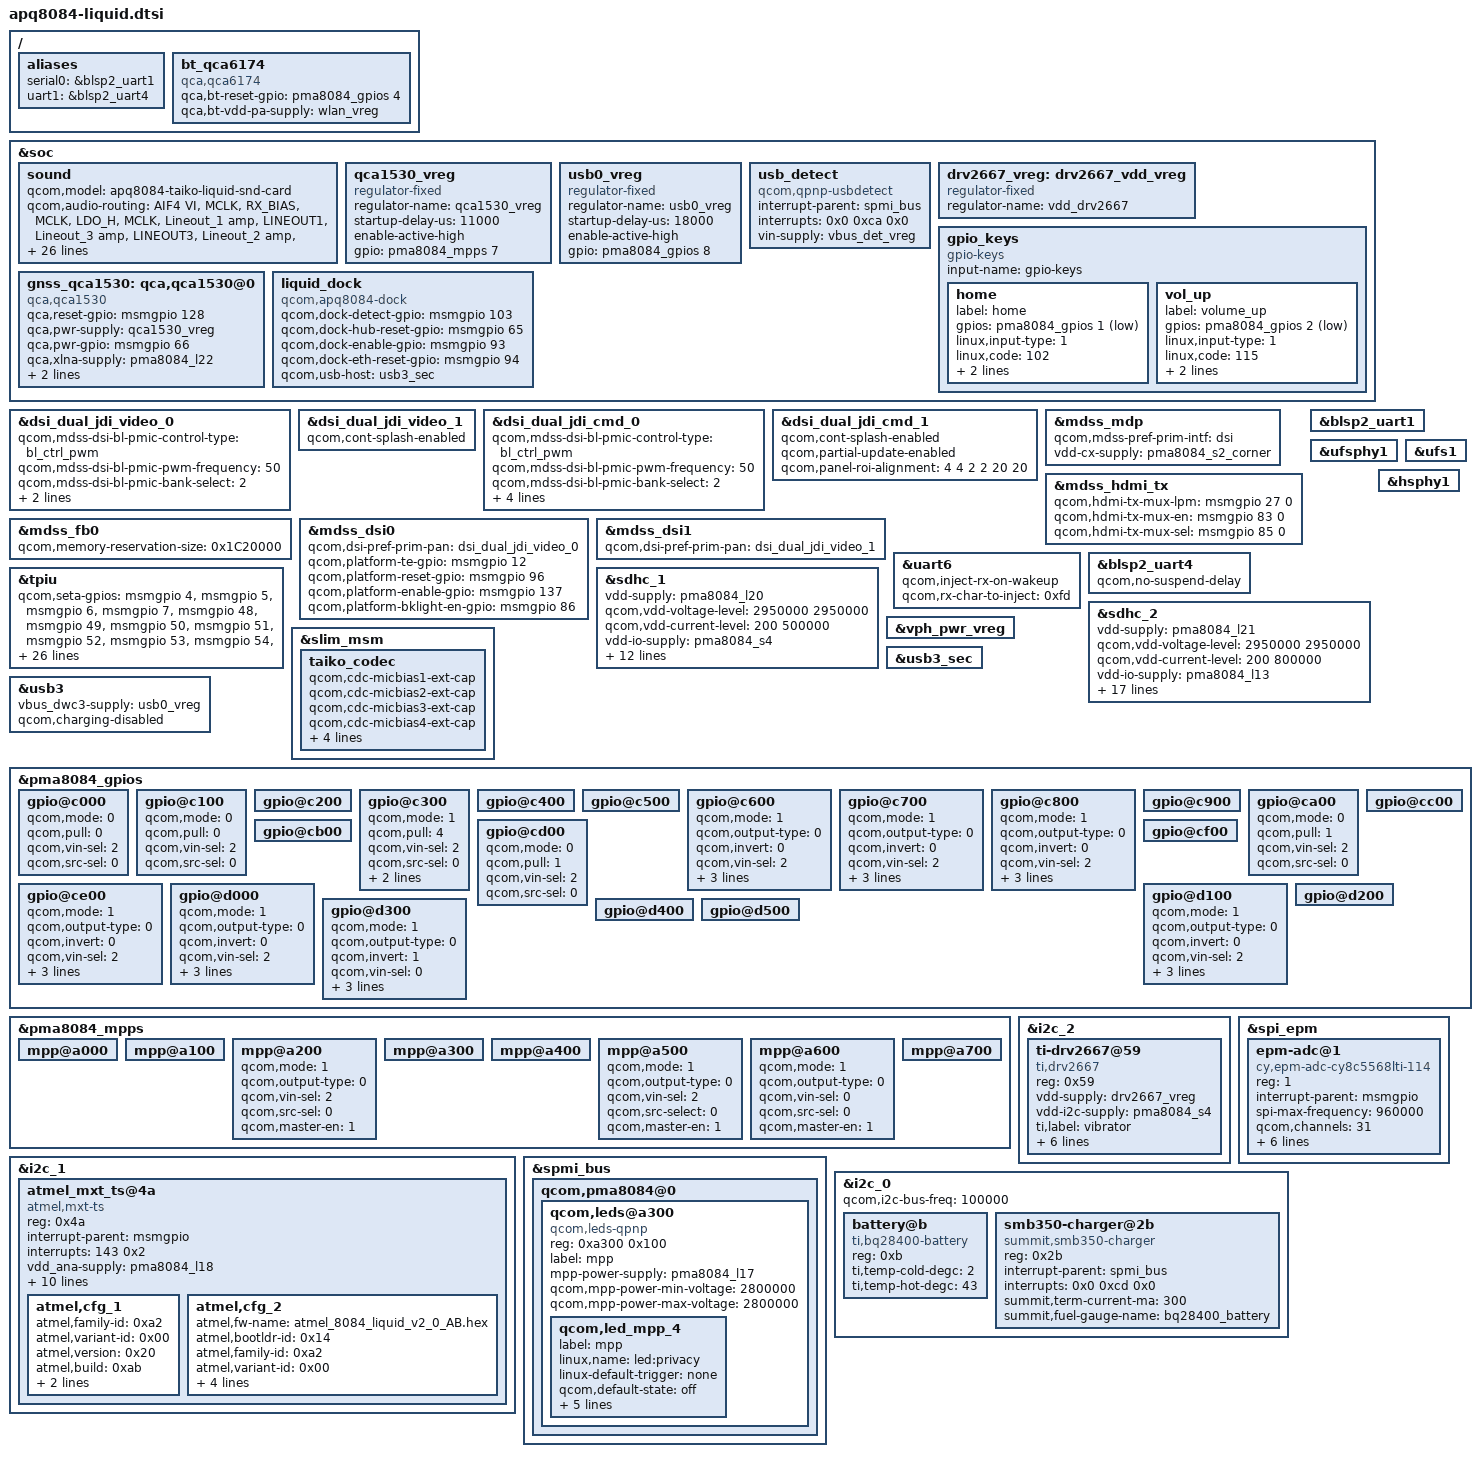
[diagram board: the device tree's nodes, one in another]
/* Copyright (c) 2013-2014, The Linux Foundation. All rights reserved.
 *
 * This program is free software; you can redistribute it and/or modify
 * it under the terms of the GNU General Public License version 2 and
 * only version 2 as published by the Free Software Foundation.
 *
 * This program is distributed in the hope that it will be useful,
 * but WITHOUT ANY WARRANTY; without even the implied warranty of
 * MERCHANTABILITY or FITNESS FOR A PARTICULAR PURPOSE.  See the
 * GNU General Public License for more details.
 */

/ {
	aliases {
		serial0 = &blsp2_uart1;
		uart1 = &blsp2_uart4;
	};

	bt_qca6174 {
		compatible = "qca,qca6174";
		qca,bt-reset-gpio = <&pma8084_gpios 4 0>; /* BT_EN */
		qca,bt-vdd-pa-supply = <&wlan_vreg>;
	};
};

&soc {
	sound {
		qcom,model = "apq8084-taiko-liquid-snd-card";

		qcom,audio-routing =
			"AIF4 VI", "MCLK",
			"RX_BIAS", "MCLK",
			"LDO_H", "MCLK",
			"Lineout_1 amp", "LINEOUT1",
			"Lineout_3 amp", "LINEOUT3",
			"Lineout_2 amp", "LINEOUT2",
			"Lineout_4 amp", "LINEOUT4",
			"SPK_ultrasound amp", "SPK_OUT",
			"AMIC1", "MIC BIAS3 External",
			"MIC BIAS3 External", "Analog Mic7",
			"AMIC2", "MIC BIAS2 External",
			"MIC BIAS2 External", "Headset Mic",
			"AMIC3", "MIC BIAS2 External",
			"MIC BIAS2 External", "ANCLeft Headset Mic",
			"AMIC4", "MIC BIAS2 External",
			"MIC BIAS2 External", "ANCRight Headset Mic",
			"DMIC1", "MIC BIAS4 External",
			"MIC BIAS4 External", "Digital Mic4",
			"DMIC2", "MIC BIAS3 External",
			"MIC BIAS3 External", "Digital Mic3",
			"DMIC3", "MIC BIAS1 External",
			"MIC BIAS1 External", "Digital Mic2",
			"DMIC4", "MIC BIAS1 External",
			"MIC BIAS1 External", "Digital Mic1",
			"DMIC5", "MIC BIAS3 External",
			"MIC BIAS3 External", "Digital Mic5",
			"DMIC6", "MIC BIAS3 External",
			"MIC BIAS3 External", "Digital Mic6";

		qcom,cdc-micbias2-headset-only;
		qcom,hdmi-audio-rx;
		asoc-codec = <&stub_codec>, <&hdmi_audio>;
		asoc-codec-names = "msm-stub-codec.1", "msm-hdmi-audio-codec-rx";
		qcom,ext-spk-amp-supply = <&hdmi_vreg>;
		qcom,ext-spk-amp-gpio = <&pma8084_mpps 6 0>;
		qcom,dock-plug-det-irq = <&msmgpio 142 0>;
	};

	qca1530_vreg: qca1530_vreg {
		compatible = "regulator-fixed";
		regulator-name = "qca1530_vreg";
		startup-delay-us = <11000>; /* the on time of SMB209AN */
		enable-active-high;
		gpio = <&pma8084_mpps 7 0>;
	};

	usb0_vreg: usb0_vreg {
		compatible = "regulator-fixed";
		regulator-name = "usb0_vreg";
		startup-delay-us = <18000>; /* the on time of TPD4S214 */
		enable-active-high;
		gpio = <&pma8084_gpios 8 0>;
	};

	usb_detect {
		compatible = "qcom,qpnp-usbdetect";
		interrupt-parent = <&spmi_bus>;
		interrupts = <0x0 0xca 0x0>;  /* PMA8084 GPIO 11 */
		interrupt-names = "vbus_det_irq";
		vin-supply = <&vbus_det_vreg>;
	};

	drv2667_vreg: drv2667_vdd_vreg {
		compatible = "regulator-fixed";
		regulator-name = "vdd_drv2667";
	};

	gpio_keys {
		compatible = "gpio-keys";
		input-name = "gpio-keys";

		home {
			label = "home";
			gpios = <&pma8084_gpios 1 0x1>;
			linux,input-type = <1>;
			linux,code = <102>;
			gpio-key,wakeup;
			debounce-interval = <15>;
		};

		vol_up {
			label = "volume_up";
			gpios = <&pma8084_gpios 2 0x1>;
			linux,input-type = <1>;
			linux,code = <115>;
			gpio-key,wakeup;
			debounce-interval = <15>;
		};
	};

	gnss_qca1530: qca,qca1530@0 {
		compatible = "qca,qca1530";
		qca,reset-gpio = <&msmgpio 128 0>;
		qca,pwr-supply = <&qca1530_vreg>;
		qca,pwr-gpio = <&msmgpio 66 0>;
		qca,xlna-supply = <&pma8084_l22>;
		qca,xlna-voltage-level = <3000000 3000000>;
		qca,xlna-current-level = <90000 100>;
	};

	liquid_dock {
		compatible = "qcom,apq8084-dock";
		qcom,dock-detect-gpio = <&msmgpio 103 0>;
		qcom,dock-hub-reset-gpio = <&msmgpio 65 0>;
		qcom,dock-enable-gpio = <&msmgpio 93 0>;
		qcom,dock-eth-reset-gpio = <&msmgpio 94 0>;
		qcom,usb-host = <&usb3_sec>;
	};
};

#include "apq8084-mdss-panels.dtsi"

&dsi_dual_jdi_video_0 {
	qcom,mdss-dsi-bl-pmic-control-type = "bl_ctrl_pwm";
	qcom,mdss-dsi-bl-pmic-pwm-frequency = <50>;
	qcom,mdss-dsi-bl-pmic-bank-select = <2>;
	qcom,mdss-dsi-pwm-gpio = <&pma8084_gpios 7 0>;
	qcom,cont-splash-enabled;
};

&dsi_dual_jdi_video_1 {
	qcom,cont-splash-enabled;
};


&dsi_dual_jdi_cmd_0 {
	qcom,mdss-dsi-bl-pmic-control-type = "bl_ctrl_pwm";
	qcom,mdss-dsi-bl-pmic-pwm-frequency = <50>;
	qcom,mdss-dsi-bl-pmic-bank-select = <2>;
	qcom,mdss-dsi-pwm-gpio = <&pma8084_gpios 7 0>;
	qcom,cont-splash-enabled;
	/delete-property/ qcom,cmd-sync-wait-broadcast;
	qcom,partial-update-enabled;
	qcom,panel-roi-alignment = <4 4 2 2 20 20>;
};

&dsi_dual_jdi_cmd_1 {
	qcom,cont-splash-enabled;
	/delete-property/ qcom,cmd-sync-wait-broadcast;
	/delete-property/ qcom,cmd-sync-wait-trigger;
	qcom,partial-update-enabled;
	qcom,panel-roi-alignment = <4 4 2 2 20 20>;
};


&mdss_mdp {
	qcom,mdss-pref-prim-intf = "dsi";
	vdd-cx-supply = <&pma8084_s2_corner>;
};

&mdss_hdmi_tx {
        qcom,hdmi-tx-mux-lpm = <&msmgpio 27 0>;
        qcom,hdmi-tx-mux-en = <&msmgpio 83 0>;
        qcom,hdmi-tx-mux-sel = <&msmgpio 85 0>;
};

&mdss_fb0 {
	qcom,memory-reservation-size = <0x1C20000>;
};

&mdss_dsi0 {
	qcom,dsi-pref-prim-pan = <&dsi_dual_jdi_video_0>;
	qcom,platform-te-gpio = <&msmgpio 12 0>;
	qcom,platform-reset-gpio = <&msmgpio 96 0>;
	qcom,platform-enable-gpio = <&msmgpio 137 0>;
	qcom,platform-bklight-en-gpio = <&msmgpio 86 0>;
};

&mdss_dsi1 {
	qcom,dsi-pref-prim-pan = <&dsi_dual_jdi_video_1>;
};

&uart6 {
	qcom,inject-rx-on-wakeup;
	qcom,rx-char-to-inject = <0xfd>;
	status = "ok";
};

&blsp2_uart1 {
	status = "ok";
};

&blsp2_uart4 {
	qcom,no-suspend-delay;
	status = "ok";
};

/* CoreSight */
&tpiu {
	qcom,seta-gpios = <&msmgpio 4 0>,
			  <&msmgpio 5 0>,
			  <&msmgpio 6 0>,
			  <&msmgpio 7 0>,
			  <&msmgpio 48 0>,
			  <&msmgpio 49 0>,
			  <&msmgpio 50 0>,
			  <&msmgpio 51 0>,
			  <&msmgpio 52 0>,
			  <&msmgpio 53 0>,
			  <&msmgpio 54 0>,
			  <&msmgpio 55 0>,
			  <&msmgpio 56 0>,
			  <&msmgpio 57 0>,
			  <&msmgpio 63 0>,
			  <&msmgpio 64 0>,
			  <&msmgpio 75 0>,
			  <&msmgpio 122 0>;
	qcom,seta-gpios-func = <4 4 4 4 5 4 4 5 5 4 4 4 4 4 4 5 2 1>;
	qcom,seta-gpios-drv =  <7 7 7 7 7 7 7 7 7 7 7 7 7 7 7 7 7 7>;
	qcom,seta-gpios-pull = <0 0 0 0 0 0 0 0 0 0 0 0 0 0 0 0 0 0>;
	qcom,seta-gpios-dir =  <2 2 2 2 2 2 2 2 2 2 2 2 2 2 2 2 2 2>;

	qcom,setb-gpios = <&msmgpio 10 0>,
			  <&msmgpio 11 0>,
			  <&msmgpio 29 0>,
			  <&msmgpio 30 0>,
			  <&msmgpio 39 0>,
			  <&msmgpio 40 0>,
			  <&msmgpio 43 0>,
			  <&msmgpio 44 0>,
			  <&msmgpio 45 0>,
			  <&msmgpio 46 0>,
			  <&msmgpio 67 0>,
			  <&msmgpio 68 0>,
			  <&msmgpio 69 0>,
			  <&msmgpio 70 0>,
			  <&msmgpio 71 0>,
			  <&msmgpio 72 0>,
			  <&msmgpio 102 0>,
			  <&msmgpio 121 0>;
	qcom,setb-gpios-func = <4 4 5 4 4 4 4 4 4 4 3 3 2 4 3 3 2 1>;
	qcom,setb-gpios-drv =  <7 7 7 7 7 7 7 7 7 7 7 7 7 7 7 7 7 7>;
	qcom,setb-gpios-pull = <0 0 0 0 0 0 0 0 0 0 0 0 0 0 0 0 0 0>;
	qcom,setb-gpios-dir =  <2 2 2 2 2 2 2 2 2 2 2 2 2 2 2 2 2 2>;
};

&ufsphy1 {
	status = "ok";
};

&ufs1 {
	status = "ok";
};

&sdhc_1 {
	vdd-supply = <&pma8084_l20>;
	qcom,vdd-voltage-level = <2950000 2950000>;
	qcom,vdd-current-level = <200 500000>;

	vdd-io-supply = <&pma8084_s4>;
	qcom,vdd-io-always-on;
	qcom,vdd-io-voltage-level = <1800000 1800000>;
	qcom,vdd-io-current-level = <200 154000>;

	pinctrl-names = "active", "sleep";
	pinctrl-0 = <&sdc1_clk_on &sdc1_cmd_on &sdc1_data_on &sdc1_rclk_on>;
	pinctrl-1 = <&sdc1_clk_off &sdc1_cmd_off &sdc1_data_off &sdc1_rclk_off>;

	qcom,clk-rates = <400000 20000000 25000000 50000000 100000000 192000000 384000000>;
	qcom,nonremovable;
	qcom,bus-speed-mode = "HS400_1p8v", "HS200_1p8v", "DDR_1p8v";
	status = "ok";
};

&sdhc_2 {
	vdd-supply = <&pma8084_l21>;
	qcom,vdd-voltage-level = <2950000 2950000>;
	qcom,vdd-current-level = <200 800000>;

	vdd-io-supply = <&pma8084_l13>;
	qcom,vdd-io-voltage-level = <1800000 2950000>;
	qcom,vdd-io-current-level = <200 22000>;

	pinctrl-names = "active", "sleep";
	pinctrl-0 = <&sdc2_clk_on &sdc2_cmd_on &sdc2_data_on &sdhc2_cd_on>;
	pinctrl-1 = <&sdc2_clk_off &sdc2_cmd_off &sdc2_data_off &sdhc2_cd_off>;

	qcom,clk-rates = <400000 20000000 25000000 50000000 100000000 200000000>;
	qcom,bus-speed-mode = "SDR12", "SDR25", "SDR50", "DDR50", "SDR104";

	#address-cells = <0>;
	interrupt-parent = <&sdhc_2>;
	interrupts = <0 1 2>;
	#interrupt-cells = <1>;
	interrupt-map-mask = <0xffffffff>;
	interrupt-map = <0 &intc 0 125 0
			1 &intc 0 221 0
			2 &msmgpio 122 0x3>;
	interrupt-names = "hc_irq", "pwr_irq", "status_irq";
	cd-gpios = <&msmgpio 122 0x1>;
	wp-gpios = <&msmgpio 75 0x1>;

	status = "ok";
};

&vph_pwr_vreg {
	status = "ok";
};

&slim_msm {
	taiko_codec {
		qcom,cdc-micbias1-ext-cap;
		qcom,cdc-micbias2-ext-cap;
		qcom,cdc-micbias3-ext-cap;
		qcom,cdc-micbias4-ext-cap;

		/*
		 * Liquid has external spkrdrv supply. Give a dummy supply
		 * to make codec driver happy.
		 */
		cdc-vdd-spkdrv-supply = <&vph_pwr_vreg>;
		qcom,cdc-vdd-spkdrv-voltage = <0 0>;
		qcom,cdc-vdd-spkdrv-current = <0>;

		qcom,cdc-on-demand-supplies = "cdc-vdd-spkdrv";
	};
};

&usb3 {
	vbus_dwc3-supply = <&usb0_vreg>;
	qcom,charging-disabled;
};

&usb3_sec {
	status = "ok";
};

&hsphy1 {
	status = "ok";
};

&pma8084_gpios {
	gpio@c000 { /* GPIO 1 */
		qcom,mode = <0>;
		qcom,pull = <0>;
		qcom,vin-sel = <2>;
		qcom,src-sel = <0>;
	};

	gpio@c100 { /* GPIO 2 */
		qcom,mode = <0>;
		qcom,pull = <0>;
		qcom,vin-sel = <2>;
		qcom,src-sel = <0>;
	};

	gpio@c200 { /* GPIO 3 */
	};

	gpio@c300 { /* GPIO 4 */
                qcom,mode = <1>;         /* Digital output*/
                qcom,pull = <4>;         /* Pulldown 10uA */
                qcom,vin-sel = <2>;      /* VIN2 */
                qcom,src-sel = <0>;      /* GPIO */
                qcom,invert = <0>;       /* Invert */
                qcom,master-en = <1>;    /* Enable GPIO */
	};

	gpio@c400 { /* GPIO 5 */
	};

	gpio@c500 { /* GPIO 6 */
	};

	gpio@c600 { /* GPIO 7 */
		/* Backlight PWM */
		qcom,mode = <1>;		/* Digital output */
		qcom,output-type = <0>;		/* CMOS logic */
		qcom,invert = <0>;		/* Do not invert the output */
		qcom,vin-sel = <2>;		/* PMA8084 S4 = 1.8 V */
		qcom,src-sel = <2>;		/* Special Function 1=LPG 3 */
		qcom,out-strength = <3>;	/* High drive strength */
		qcom,master-en = <1>;
	};

	gpio@c700 { /* GPIO 8 */
		qcom,mode = <1>;		/* Digital output */
		qcom,output-type = <0>;		/* CMOS logic */
		qcom,invert = <0>;		/* Output low initially */
		qcom,vin-sel = <2>;		/* VPH_PWR */
		qcom,src-sel = <0>;		/* Constant */
		qcom,out-strength = <1>;	/* Low */
		qcom,master-en = <1>;		/* Enable GPIO */
	};

	gpio@c800 { /* GPIO 9 */
		qcom,mode = <1>;		/* Digital output */
		qcom,output-type = <0>;		/* CMOS logic */
		qcom,invert = <0>;		/* Output low initially */
		qcom,vin-sel = <2>;		/* VPH_PWR */
		qcom,src-sel = <0>;		/* Constant */
		qcom,out-strength = <1>;	/* Low */
		qcom,master-en = <1>;		/* Enable GPIO */
	};

	gpio@c900 { /* GPIO 10 */
	};

	gpio@ca00 { /* GPIO 11 */
		/* VBUS interrupt */
		qcom,mode = <0>;
		qcom,pull = <1>;
		qcom,vin-sel = <2>;
		qcom,src-sel = <0>;
	};

	gpio@cb00 { /* GPIO 12 */
	};

	gpio@cc00 { /* GPIO 13 */
	};

	gpio@cd00 { /* GPIO 14 */
		qcom,mode = <0>;
		qcom,pull = <1>;
		qcom,vin-sel = <2>;
		qcom,src-sel = <0>;
	};

	gpio@ce00 { /* GPIO 15 */
		qcom,mode = <1>;		/* Digital output */
		qcom,output-type = <0>;		/* CMOS logic */
		qcom,invert = <0>;		/* Output low initially */
		qcom,vin-sel = <2>;		/* VIN 2 */
		qcom,src-sel = <2>;		/* Function 1 */
		qcom,out-strength = <2>;	/* Medium */
		qcom,master-en = <1>;		/* Enable GPIO */
	};

	gpio@cf00 { /* GPIO 16 */
	};

	gpio@d000 { /* GPIO 17 */
		qcom,mode = <1>;		/* Digital output */
		qcom,output-type = <0>;		/* CMOS logic */
		qcom,invert = <0>;		/* Output low initially */
		qcom,vin-sel = <2>;		/* VIN 2 */
		qcom,src-sel = <3>;		/* Function 2 */
		qcom,out-strength = <2>;	/* Medium */
		qcom,master-en = <1>;		/* Enable GPIO */
	};

	gpio@d100 { /* GPIO 18 */
		qcom,mode = <1>;		/* Digital output */
		qcom,output-type = <0>;		/* CMOS logic */
		qcom,invert = <0>;		/* Output low initially */
		qcom,vin-sel = <2>;		/* VIN 2 */
		qcom,src-sel = <3>;		/* Function 2 */
		qcom,out-strength = <2>;	/* Medium */
		qcom,master-en = <1>;		/* Enable GPIO */
	};

	gpio@d200 { /* GPIO 19 */
	};

	gpio@d300 { /* GPIO 20 */
		qcom,mode = <1>;		/* Digital output */
		qcom,output-type = <0>;		/* CMOS logic */
		qcom,invert = <1>;		/* Output high */
		qcom,vin-sel = <0>;		/* VPH_PWR */
		qcom,src-sel = <0>;		/* Constant */
		qcom,out-strength = <1>;	/* Low */
		qcom,master-en = <1>;		/* Enable GPIO */
	};

	gpio@d400 { /* GPIO 21 */
	};

	gpio@d500 { /* GPIO 22 */
	};
};

&pma8084_mpps {
	mpp@a000 { /* MPP 1 */
	};

	mpp@a100 { /* MPP 2 */
	};

	mpp@a200 { /* MPP 3 */
		/* HDMI_5v_vreg regulator enable */
		qcom,mode = <1>;		/* Digital output */
		qcom,output-type = <0>;		/* CMOS logic */
		qcom,vin-sel = <2>;		/* VPH_PWR */
		qcom,src-sel = <0>;		/* Constant */
		qcom,master-en = <1>;		/* Enable GPIO */
	};

	mpp@a300 { /* MPP 4 */
	};

	mpp@a400 { /* MPP 5 */
	};

	mpp@a500 { /* MPP 6 */
		/* CLASS_D_EN speakers PA */
		qcom,mode = <1>;		/* DIG_OUT */
		qcom,output-type = <0>;		/* PNP_PIN_OUT_BUF_CMOS */
		qcom,vin-sel = <2>;		/* S3A 1.8v */
		qcom,src-select = <0>;		/* CONSTANT */
		qcom,master-en = <1>;		/* ENABLE MPP */
	};

	mpp@a600 { /* MPP 7 */
		/* QCA1350_vreg regulator enable */
		qcom,mode = <1>;		/* Digital output */
		qcom,output-type = <0>;		/* CMOS logic */
		qcom,vin-sel = <0>;		/* VPH_PWR */
		qcom,src-sel = <0>;		/* Constant */
		qcom,master-en = <1>;		/* Enable GPIO */
	};

	mpp@a700 { /* MPP 8 */
	};
};

&i2c_1 {
	atmel_mxt_ts@4a {
		compatible = "atmel,mxt-ts";
		reg = <0x4a>;
		interrupt-parent = <&msmgpio>;
		interrupts = <143 0x2>;
		vdd_ana-supply = <&pma8084_l18>;
		vcc_i2c-supply = <&pma8084_lvs1>;
		atmel,reset-gpio = <&msmgpio 145 0x00>;
		atmel,i2cmode-gpio = <&msmgpio 144 0x00>;
		atmel,irq-gpio = <&msmgpio 143 0x00>;
		atmel,panel-coords = <0 0 2560 1440>;
		atmel,display-coords = <0 0 2560 1440>;
		atmel,i2c-pull-up;
		atmel,no-force-update;
		atmel,no-lpm-support;
		atmel,bl-addr = <0x26>;
		atmel,cfg_1 {
			atmel,family-id = <0xa2>;
			atmel,variant-id = <0x00>;
			atmel,version = <0x20>;
			atmel,build = <0xab>;
			atmel,config = [
				/* Object 6, Instance = 0 */
				00 00 00 00 00 00
				/* Object 38, Instance = 0 */
				21 03 00 1B 0B 0D 00 00 00 00
				00 00 00 00 00 00 00 00 00 00
				00 00 00 00 00 00 00 00 00 00
				00 00 00 00 00 00 00 00 00 00
				00 00 00 00 00 00 00 00 00 00
				00 00 00 00 00 00 00 00 00 00
				00 00 00 00
				/* Object 71, Instance = 0 */
				00 00 00 00 00 00 00 00 00 00
				00 00 00 00 00 00 00 00 00 00
				00 00 00 00 00 00 00 00 00 00
				00 00 00 00 00 00 00 00 00 00
				00 00 00 00 00 00 00 00 00 00
				00 00 00 00 00 00 00 00 00 00
				00 00 00 00 00 00 00 00 00 00
				00 00 00 00 00 00 00 00 00 00
				00 00 00 00 00 00 00 00 00 00
				00 00 00 00 00 00 00 00 00 00
				00 00 00 00 00 00 00 00 00 00
				00 00 00 00 00 00 00 00 00 00
				00 00 00 00 00 00 00 00 00 00
				00 00 00 00 00 00 00 00 00 00
				00 00 00 00 00 00 00 00 00 00
				00 00 00 00 00 00 00 00 00 00
				00 00 00 00 00 00 00 00
				/* Object 7, Instance = 0 */
				21 08 0A 40
				/* Object 8, Instance = 0 */
				46 00 14 00 00 00 00 0A 32 19
				/* Object 9, Instance = 0 */
				83 00 00 20 34 00 AF 4B 01 07
				0A 0C 03 00 0A 05 0A 00 A0 05
				00 0A 03 07 04 00 08 14 1A 0D
				23 0A 00 00 00 00 00 00 00 00
				00 00 00 00 00 00 00
				/* Object 15, Instance = 0 */
				00 00 00 00 00 00 00 00 00 00
				00
				/* Object 18, Instance = 0 */
				00 00
				/* Object 19, Instance = 0 */
				00 00 00 00 00 00
				/* Object 24, Instance = 0 */
				00 00 00 00 00 00 00 00 00 00
				00 00 00 00 00 00 00 00 00
				/* Object 25, Instance = 0 */
				01 00 00 00 00 00 00 00 00 00
				00 00 00 00 C8 00 00 00 00 00
				00
				/* Object 27, Instance = 0 */
				00 00 00 00 00 00 00
				/* Object 40, Instance = 0 */
				00 00 00 00 00
				/* Object 42, Instance = 0 */
				33 14 26 1C 64 00 00 00 05 01
				00 04 00
				/* Object 43, Instance = 0 */
				00 00 91 00 01 01 80 00 00 00
				00 00
				/* Object 46, Instance = 0 */
				00 00 10 18 00 00 01 00 00 1F
				05
				/* Object 47, Instance = 0 */
				01 0F 1E 06 03 28 00 C8 02 23
				CE CE 03 00 00 00 00 00 00 00
				00 00 00 00 00 00 00 00
				/* Object 55, Instance = 0 */
				00 5A 14 0A 10 00 00
				/* Object 56, Instance = 0 */
				01 00 01 19 0D 0D 0D 0D 0D 0D
				0D 0D 0E 0E 0E 0E 0E 0E 0E 0E
				0F 0F 0F 0F 0F 0F 0F 0F 0F 0F
				0F 0F 0F 0F 0F 0F 00 00 01 02
				06 04 00 00 00 00 00 00 00 00
				00
				/* Object 57, Instance = 0 */
				00 00 00
				/* Object 61, Instance = 0 */
				00 00 00 00 00
				/* Object 62, Instance = 0 */
				7D 63 40 1A 00 07 20 00 00 00
				02 03 05 07 05 00 0A 05 05 AF
				1E 1E 34 0A 40 00 00 00 00 00
				00 00 00 00 00 00 00 00 00 00
				00 00 00 00 00 00 00 00 00 00
				00 00 00 00 00 00 00 00 00 00
				00 00 00 00 00 00 00 00 00 00
				00 00 00 00
				/* Object 63, Instance = 0 */
				00 00 00 00 00 00 00 00 00 00
				00 00 00 00 00 00 00 00 00 00
				00 00 00 00 00
				/* Object 65, Instance = 0 */
				00 00 00 00 00 00 00 00 00 00
				00 00 00 00 00 00 00
				/* Object 66, Instance = 0 */
				00 00 00
				/* Object 70, Instance = 0 */
				00 00 00 00 00 00 00 00 00 00
				/* Object 73, Instance = 0 */
				00 00 00 00 00 00
				/* Object 77, Instance = 0 */
				00 00 00 00
				/* Object 79, Instance = 0 */
				00 00 00
				];
		};
		atmel,cfg_2 {
			atmel,fw-name = "atmel_8084_liquid_v2_0_AB.hex";
			atmel,bootldr-id = <0x14>;
			atmel,family-id = <0xa2>;
			atmel,variant-id = <0x00>;
			atmel,version = <0x20>;
			atmel,build = <0xaa>;
			atmel,config = [
				/* Object 6, Instance = 0 */
				00 00 00 00 00 00
				/* Object 38, Instance = 0 */
				21 03 00 1B 0B 0D 00 00 00 00
				00 00 00 00 00 00 00 00 00 00
				00 00 00 00 00 00 00 00 00 00
				00 00 00 00 00 00 00 00 00 00
				00 00 00 00 00 00 00 00 00 00
				00 00 00 00 00 00 00 00 00 00
				00 00 00 00
				/* Object 71, Instance = 0 */
				00 00 00 00 00 00 00 00 00 00
				00 00 00 00 00 00 00 00 00 00
				00 00 00 00 00 00 00 00 00 00
				00 00 00 00 00 00 00 00 00 00
				00 00 00 00 00 00 00 00 00 00
				00 00 00 00 00 00 00 00 00 00
				00 00 00 00 00 00 00 00 00 00
				00 00 00 00 00 00 00 00 00 00
				00 00 00 00 00 00 00 00 00 00
				00 00 00 00 00 00 00 00 00 00
				00 00 00 00 00 00 00 00 00 00
				00 00 00 00 00 00 00 00 00 00
				00 00 00 00 00 00 00 00 00 00
				00 00 00 00 00 00 00 00 00 00
				00 00 00 00 00 00 00 00 00 00
				00 00 00 00 00 00 00 00 00 00
				00 00 00 00 00 00 00 00
				/* Object 7, Instance = 0 */
				21 08 0A 40
				/* Object 8, Instance = 0 */
				46 00 14 00 00 00 00 0A 32 19
				/* Object 9, Instance = 0 */
				83 00 00 20 34 00 AF 4B 01 07
				0A 0C 03 00 0A 05 0A 00 A0 05
				00 0A 03 07 04 00 08 14 1A 0D
				23 0A 00 00 00 00 00 00 00 00
				00 00 00 00 00 00 00
				/* Object 15, Instance = 0 */
				00 00 00 00 00 00 00 00 00 00
				00
				/* Object 18, Instance = 0 */
				00 00
				/* Object 19, Instance = 0 */
				00 00 00 00 00 00
				/* Object 24, Instance = 0 */
				00 00 00 00 00 00 00 00 00 00
				00 00 00 00 00 00 00 00 00
				/* Object 25, Instance = 0 */
				01 00 00 00 00 00 00 00 00 00
				00 00 00 00 C8 00 00 00 00 00
				00
				/* Object 27, Instance = 0 */
				00 00 00 00 00 00 00
				/* Object 40, Instance = 0 */
				00 00 00 00 00
				/* Object 42, Instance = 0 */
				33 14 26 1C 64 00 00 00 05 01
				00 04 00
				/* Object 43, Instance = 0 */
				00 00 91 00 01 01 80 00 00 00
				00 00
				/* Object 46, Instance = 0 */
				00 00 10 18 00 00 01 00 00 1F
				05
				/* Object 47, Instance = 0 */
				01 0F 1E 06 03 28 00 C8 02 23
				32 32 03 00 00 00 00 00 00 00
				00 00 00 00 00 00 00 00
				/* Object 55, Instance = 0 */
				00 5A 14 0A 10 00 00
				/* Object 56, Instance = 0 */
				01 00 01 19 0D 0D 0D 0D 0D 0D
				0D 0D 0E 0E 0E 0E 0E 0E 0E 0E
				0F 0F 0F 0F 0F 0F 0F 0F 0F 0F
				0F 0F 0F 0F 0F 0F 00 00 01 02
				06 04 00 00 00 00 00 00 00 00
				00
				/* Object 57, Instance = 0 */
				00 00 00
				/* Object 61, Instance = 0 */
				00 00 00 00 00
				/* Object 62, Instance = 0 */
				7D 63 40 1A 00 07 20 00 00 00
				02 03 05 07 05 00 0A 05 05 AF
				1E 1E 34 0A 40 00 00 00 00 00
				00 00 00 00 00 00 00 00 00 00
				00 00 00 00 00 00 00 00 00 00
				00 00 00 00 00 00 00 00 00 00
				00 00 00 00 00 00 00 00 00 00
				00 00 00 00
				/* Object 63, Instance = 0 */
				00 00 00 00 00 00 00 00 00 00
				00 00 00 00 00 00 00 00 00 00
				00 00 00 00 00
				/* Object 65, Instance = 0 */
				00 00 00 00 00 00 00 00 00 00
				00 00 00 00 00 00 00
				/* Object 66, Instance = 0 */
				00 00 00
				/* Object 70, Instance = 0 */
				00 00 00 00 00 00 00 00 00 00
				/* Object 73, Instance = 0 */
				00 00 00 00 00 00
				/* Object 77, Instance = 0 */
				00 00 00 00
				/* Object 79, Instance = 0 */
				00 00 00
				];
		};
	};
};

&i2c_2 {
	ti-drv2667@59 {
		compatible = "ti,drv2667";
		reg = <0x59>;
		vdd-supply = <&drv2667_vreg>;
		vdd-i2c-supply = <&pma8084_s4>;
		ti,label = "vibrator";
		ti,gain = <2>;
		ti,idle-timeout-ms = <20>;
		ti,max-runtime-ms = <15000>;
		ti,mode = <2>;
		ti,wav-seq = [
			/* wave form id */
			01
			/* header size, start and stop bytes */
			05 80 06 00 09
			/* repeat, amp, freq, duration, envelope */
			01 ff 19 02 00];
	};
};

&spi_epm {
	epm-adc@1 {
		compatible = "cy,epm-adc-cy8c5568lti-114";
		reg = <1>;
		interrupt-parent = <&msmgpio>;
		spi-max-frequency = <960000>;
		qcom,channels = <31>;
		qcom,gain = <50 100 50 50 50 50 100 50 100 100
				4 50 100 50 50 50 100 100 100 50
				100 100 100 50 50 50 100 1 1 1
				1>;
		qcom,rsense = <100 25 50 10 10 25 5 200 100 1000
				1000 10 100 2 25 10 10 200 200 5
				100 5 20 1000 2 2 25 1000 1000 1000
				1000>;
		qcom,channel-type = <0xf0000000>;
		qcom,epm-enable-gpio = <&msmgpio 92 0>;
	};
};

&spmi_bus {
	qcom,pma8084@0 {
		qcom,leds@a300 {
			compatible = "qcom,leds-qpnp";
			reg = <0xa300 0x100>;
			label = "mpp";
			status = "okay";
			mpp-power-supply = <&pma8084_l17>;
			qcom,mpp-power-min-voltage = <2800000>;
			qcom,mpp-power-max-voltage = <2800000>;
			qcom,led_mpp_4 {
				label = "mpp";
				linux,name = "led:privacy";
				linux-default-trigger = "none";
				qcom,default-state = "off";
				qcom,max-current = <40>;
				qcom,id = <6>;
				qcom,source-sel = <1>;
				qcom,mode-ctrl = <0x60>;
				qcom,mode = "manual";
			};
		};
	};
};

&i2c_0 {
	qcom,i2c-bus-freq = <100000>;

	battery@b {
		compatible = "ti,bq28400-battery";
		reg = <0xb>;
		ti,temp-cold-degc = <2>;
		ti,temp-hot-degc = <43>;
	};

	smb350-charger@2b {
		compatible = "summit,smb350-charger";
		reg = <0x2b>; /* 0x56/0x57 */
		interrupt-parent = <&spmi_bus>;
		interrupts = <0x0 0xcd 0x0>;	/* PMA8084 GPIO 14 */
		summit,term-current-ma = <300>;
		summit,fuel-gauge-name = "bq28400_battery";
	};
};
